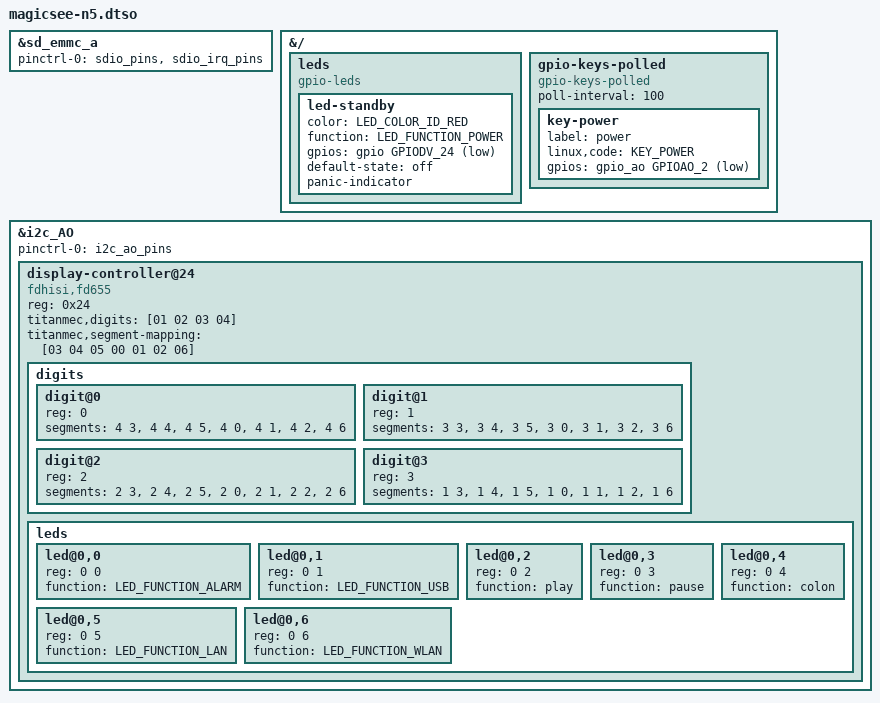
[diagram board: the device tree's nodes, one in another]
/dts-v1/;
/plugin/;

#include <dt-bindings/gpio/gpio.h>
#include <dt-bindings/input/input.h>
#include <dt-bindings/leds/common.h>
#include <dt-bindings/gpio/meson-gxl-gpio.h>

&sd_emmc_a {
	pinctrl-0 = <&sdio_pins>, <&sdio_irq_pins>;
};

&{/} {

	leds {
		compatible = "gpio-leds";

		led-standby {
			color = <LED_COLOR_ID_RED>;
			function = LED_FUNCTION_POWER;
			gpios = <&gpio GPIODV_24 GPIO_ACTIVE_LOW>;
			default-state = "off";
			panic-indicator;
		};
	};

	gpio-keys-polled {
		compatible = "gpio-keys-polled";
		poll-interval = <100>;

		key-power {
			label = "power";
			linux,code = <KEY_POWER>;
			gpios = <&gpio_ao GPIOAO_2 GPIO_ACTIVE_LOW>;
		};
	};

};

&i2c_AO {
	status = "okay";
	pinctrl-0 = <&i2c_ao_pins>;
	pinctrl-names = "default";

	#address-cells = <1>;
	#size-cells = <0>;

	display-controller@24 {
		compatible = "fdhisi,fd655";
		reg = <0x24>;

		titanmec,digits = [01 02 03 04];
		titanmec,segment-mapping = [03 04 05 00 01 02 06];

		digits {
			#address-cells = <1>;
			#size-cells = <0>;

			digit@0 {
				reg = <0>;
				segments = <4 3>, <4 4>, <4 5>, <4 0>, <4 1>, <4 2>, <4 6>;
			};
			digit@1 {
				reg = <1>;
				segments = <3 3>, <3 4>, <3 5>, <3 0>, <3 1>, <3 2>, <3 6>;
			};
			digit@2 {
				reg = <2>;
				segments = <2 3>, <2 4>, <2 5>, <2 0>, <2 1>, <2 2>, <2 6>;
			};
			digit@3 {
				reg = <3>;
				segments = <1 3>, <1 4>, <1 5>, <1 0>, <1 1>, <1 2>, <1 6>;
			};
		};

		leds {
			#address-cells = <2>;
			#size-cells = <0>;

			led@0,0 {
				reg = <0 0>;
				function = LED_FUNCTION_ALARM;
			};

			led@0,1 {
				reg = <0 1>;
				function = LED_FUNCTION_USB;
			};

			led@0,2 {
				reg = <0 2>;
				function = "play";
			};

			led@0,3 {
				reg = <0 3>;
				function = "pause";
			};

			led@0,4 {
				reg = <0 4>;
				function = "colon";
			};

			led@0,5 {
				reg = <0 5>;
				function = LED_FUNCTION_LAN;
			};

			led@0,6 {
				reg = <0 6>;
				function = LED_FUNCTION_WLAN;
			};
		};

	};
};

